# nrf7120E_enga_application register map
Vendor: Nordic Semiconductor; Series: nrf71; File version: 1
CPU: CM33 r0p4, little endian, MPU, FPU, 3 interrupt priority bits, 270 interrupts, 4 SAU regions
Registers are 32-bit, read-write, reset 0x0 unless marked. A register's access mark holds for its fields unless they carry their own. Offsets are from the block's base; [hi:lo] are bit positions; lines under a group give offsets from that group; {n}, {i} and the like mark numbered series; 'fields as' and 'values as' point back to an identical list.

## GLOBAL_UICR_S — User Information Configuration Registers
Base 0x00FFD000
{0x0+0x20*i} APPROTECT[{i}] (i=0..0) group — Access Port Protection Registers
  0x00 PROTECT0 rw-once reset 0xFFFFFFFF — Description cluster: Access port protection
    [31:0] PALL
      0xFFFFFFFF=Unprotected (Leaves TAMPC PROTECT.DOMAIN DBGEN and NIDEN signal protectors unlocked and under CPU control.)
  0x1C PROTECT1 rw-once reset 0xFFFFFFFF — Description cluster: Access port protection
    fields as APPROTECT[0].PROTECT0
0x20 SECUREAPPROTECT group — Access Port Protection Registers
  0x00 PROTECT0 rw-once reset 0xFFFFFFFF — Access port protection
    [31:0] PALL
      0xFFFFFFFF=Unprotected (Leaves TAMPC PROTECT.DOMAIN SPIDEN and SPNIDEN signal protectors unlocked and under CPU control.)
  0x1C PROTECT1 rw-once reset 0xFFFFFFFF — Access port protection register
    fields as SECUREAPPROTECT.PROTECT0
0x40 AUXAPPROTECT group — Access Port Protection Registers
  0x00 PROTECT0 rw-once reset 0xFFFFFFFF — Access port protection
    [31:0] PALL
      0xFFFFFFFF=Unprotected (Leaves TAMPC PROTECT.AP DBGEN signal protector unlocked and under CPU control.)
  0x1C PROTECT1 rw-once reset 0xFFFFFFFF — Access port protection register
    fields as AUXAPPROTECT.PROTECT0
{0x60+0x20*i} ERASEPROTECT[{i}] (i=0..0) group — Erase Protection Registers
  0x00 PROTECT0 rw-once reset 0xFFFFFFFF — Description cluster: Erase protection
    [31:0] PALL
      0x50FA50FA=Protected (Erase protection is enabled and the signal protector is locked.)
  0x1C PROTECT1 rw-once reset 0xFFFFFFFF — Description cluster: Erase protection
    fields as ERASEPROTECT[0].PROTECT0
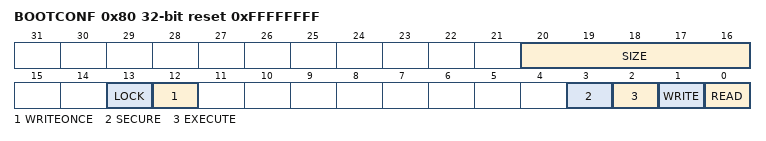
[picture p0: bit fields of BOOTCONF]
0x80 BOOTCONF rw-once reset 0xFFFFFFFF — Immutable boot region configuration.
  [20:16] SIZE — Immutable boot region size
  [13] LOCK — Enable lock of configuration register
    0=Disabled (Lock is disabled, and the MRAMC region configuration registers for the immutable boot region are writable.); 1=Enabled (Lock is enabled, and the MRAMC configuration registers for the immutable boot region are read-only.)
  [12] WRITEONCE
    0=Disabled (Write-once disabled); 1=Enabled (Write-once enabled)
  [3] SECURE — Secure access
    0=NonSecure (Both secure and non-secure access to region is allowed); 1=Secure (Only secure access to region is allowed)
  [2] EXECUTE — Execute access
    0=NotAllowed (Executing code from the region is not allowed); 1=Allowed (Executing code from the region is allowed)
  [1] WRITE — Write access
    0=NotAllowed (Writing to the region is not allowed); 1=Allowed (Writing to the region is allowed)
  [0] READ — Read access. Must be enabled in order for the Arm Cortex CPU to start executing from MRAM.
    0=NotAllowed (Reading from the region is not allowed.); 1=Allowed (Reading from the region is allowed)
0x200 USER group — Unspecified
  0x00 ROT group — Assets installed to establish initial Root of Trust in the device.
    {0x0+0x2C*k} PUBKEY[{k}] (k=0..3) group — Unspecified
      {0x0+4l} DIGEST[{l}] (l=0..7) rw-once reset 0xFFFFFFFF — Description collection: First 256 bits of SHA2-512 digest over RoT public key generation [n].
        [31:0] VALUE — Value for word [o] in the key digest [n].
      {0x20+4l} REVOKE[{l}] (l=0..2) rw-once reset 0xFFFFFFFF — Description collection: Revocation status for RoT public key generation [n].
        [31:0] STATUS — Revocation status.
          0xFFFFFFFF=NotRevoked (Key not revoked.)
    {0xB0+0x2C*k} AUTHOPKEY[{k}] (k=0..3) group — Unspecified
      {0x0+4l} DIGEST[{l}] (l=0..7) rw-once reset 0xFFFFFFFF — Description collection: First 256 bits of SHA2-512 digest over RoT authenticated operation public key generation [n].
        [31:0] VALUE — Value for word [o] in the key digest [n].
      {0x20+4l} REVOKE[{l}] (l=0..2) rw-once reset 0xFFFFFFFF — Description collection: Revocation status for RoT authenticated operation public key generation [n].
        fields as USER.ROT.PUBKEY[0].REVOKE[0]
0x400 SUPPLY group — Unspecified
  0x00 CONFIG1V8 reset 0xFFFFFFFF — Configuration of VDD_AO_1V8 supply
    [1:0] CONFIG — Configuration
      0=NORMAL (Autonomous control); 1=EXTERNAL (1V8 is supplied externally, disable LDO_VBAT_1V8 regulator); 2=HIGHLOAD (High current mode for 1V8 supply to support IO ports or external circuits. Keep LDO_VBAT_1V8 in high power mode at all times (including sleep modes).)
{0x420+8i} MACADDR[{i}] (i=0..1) group — 48-bit MAC address n
  0x00 LOW rw-once reset 0xFFFFFFFF — Description cluster: Lower 24 bits of MAC address n
    [23:0] ADDR — MAC address bits [23:0]
  0x04 HIGH rw-once reset 0xFFFFFFFF — Description cluster: Upper 24 bits of MAC address n
    [23:0] ADDR — MAC address bits [47:24]
0x440 XTALCOMP group — Crystal oscillator (XTAL) temperature compensation data
  0x00 OFFSET rw-once reset 0xFFFFFFFF — Measured XTAL frequency error at room temperature
    [31:0] OFFSET — Frequency error in ppm
  0x04 LOWTEMPTHRESHOLD rw-once reset 0xFFFFFFFF — Low temperature threshold for frequency skew compensation
    [31:0] THRESHOLD — Low temperature threshold
  0x08 LOWTEMPADJUST rw-once reset 0xFFFFFFFF — Frequency adjustment applied below the low temperature threshold
    [31:0] ADJUST — Frequency adjustment in ppm
{0x500+4i} OTP[{i}] (i=0..319) rw-once reset 0xFFFFFFFF — Description collection: One time programmable memory
  [31:0] OTP — OTP word
